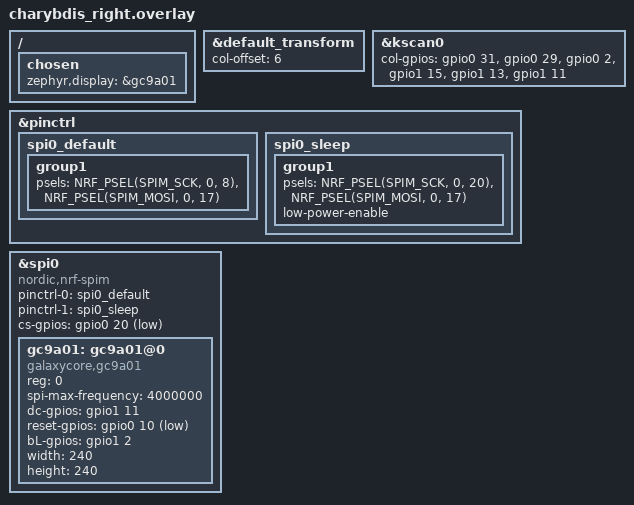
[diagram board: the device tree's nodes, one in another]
/*
 * Copyright (c) 2020 ZMK Contributors
 *
 * SPDX-License-Identifier: MIT
 */
 
#include "charybdis.dtsi"
#include <dt-bindings/zmk/matrix_transform.h>
#include <dt-bindings/pinctrl/nrf-pinctrl.h>

&default_transform {
    col-offset = <6>;
};

&kscan0 {
	col-gpios
		= <&gpio0 31 (GPIO_ACTIVE_HIGH | GPIO_PULL_DOWN)>
		, <&gpio0 29 (GPIO_ACTIVE_HIGH | GPIO_PULL_DOWN)>
		, <&gpio0 2 (GPIO_ACTIVE_HIGH | GPIO_PULL_DOWN)>
		, <&gpio1 15  (GPIO_ACTIVE_HIGH | GPIO_PULL_DOWN)>
		, <&gpio1 13 (GPIO_ACTIVE_HIGH | GPIO_PULL_DOWN)>
                , <&gpio1 11 (GPIO_ACTIVE_HIGH | GPIO_PULL_DOWN)>
;
};



/ {
    chosen {
        zephyr,display = &gc9a01;
    };
};

&pinctrl {
    spi0_default: spi0_default {
        group1 {
            /* 关键：这里定义了 SPI 总线的物理引脚 */
            psels = <NRF_PSEL(SPIM_SCK, 0, 8)>,   /* SCK 引脚: P0.08 */
                    <NRF_PSEL(SPIM_MOSI, 0, 17)>;  /* MOSI 引脚: P0.17 */
        };
    };
    spi0_sleep: spi0_sleep {
        group1 {
            psels = <NRF_PSEL(SPIM_SCK, 0, 20)>,
                    <NRF_PSEL(SPIM_MOSI, 0, 17)>;
            low-power-enable;
		};
    };
};

&spi0 {
    compatible = "nordic,nrf-spim";
	status = "okay";
    pinctrl-0 = <&spi0_default>;
    pinctrl-1 = <&spi0_sleep>;
    pinctrl-names = "default", "sleep";
    cs-gpios = <&gpio0 20 GPIO_ACTIVE_LOW>;   /* 片选 CS 引脚: P0.20 */

    gc9a01: gc9a01@0 {
        compatible = "galaxycore,gc9a01";
        reg = <0>;
        spi-max-frequency = <4000000>;        /* SPI 时钟频率 4MHz */

        /* 控制引脚：DC (Data/Command) 和 Reset */
        dc-gpios = <&gpio1 11 GPIO_ACTIVE_HIGH>;  /* DC 引脚: P1.11 */
        reset-gpios = <&gpio0 10 GPIO_ACTIVE_LOW>;      /* Reset 引脚: P0.10 */
        bL-gpios = <&gpio1 2 GPIO_ACTIVE_HIGH>;  /* 背光引脚: P1.02 */

        width = <240>;
        height = <240>;
        /* display-inversion; 若颜色反转可取消注释 */
    };
};
